# STM32MP21_CM33 register map
File version: 0.4
CPU: CM33 r0p1, little endian, MPU, FPU, vendor SysTick, 8 interrupt priority bits
Registers are 32-bit, read-write, reset 0x0 unless marked. A register's access mark holds for its fields unless they carry their own. Offsets are from the block's base; [hi:lo] are bit positions; lines under a group give offsets from that group; {n}, {i} and the like mark numbered series; 'fields as' and 'values as' point back to an identical list.

## DCMIPP (part 1 of 2) — DCMIPP register block
Base 0x48030000
Same registers: DCMIPP_S 0x58030000
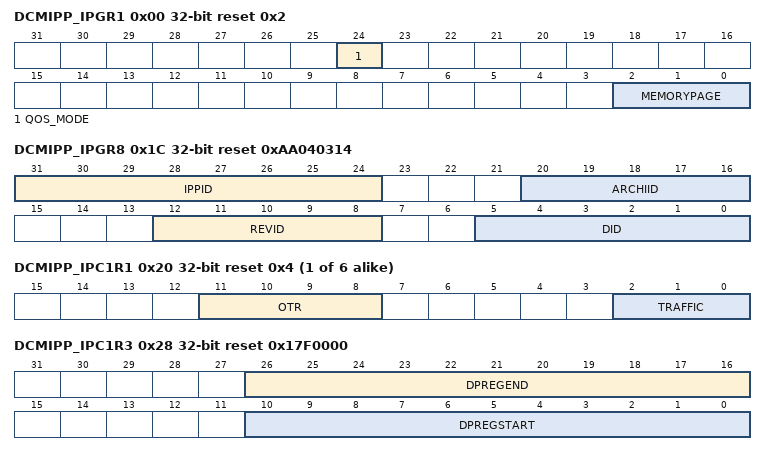
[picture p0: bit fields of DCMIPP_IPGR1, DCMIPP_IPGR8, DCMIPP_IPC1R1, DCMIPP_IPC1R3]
0x00 DCMIPP_IPGR1 reset 0x2 — DCMIPP IP-Plug global register 1
  [24] QOS_MODE — Quality of service
  [2:0] MEMORYPAGE — Memory page size, as power of 2 of 64-byte units:
    1=128 bytes; 2=256 bytes; 3=512 bytes; 4=1K bytes; 5=2K bytes; 6=4K bytes; 7=8K bytes
0x04 DCMIPP_IPGR2 — DCMIPP IP-Plug global register 2
  [0] PSTART — Request to lock the IP-Plug, to allow reconfiguration.
    0=No lock requested, IP-Plug runs on demand by background HW; 1=Lock requested: IP-Plug freezes shortly (see IDLE bit when lock is active)
0x08 DCMIPP_IPGR3 ro reset 0x1 — DCMIPP IP-Plug global register 3
  [0] IDLE — Status of IP-Plug
    0=IP-Plug is running (on demand by background HW); 1=IP-Plug is currently locked and can be reconfigured
0x1C DCMIPP_IPGR8 ro reset 0xAA040314 — DCMIPP IP-Plug identification register
  [31:24] IPPID — IP identifier (0xAA)
  [20:16] ARCHIID — Architecture identifier (0x04)
  [12:8] REVID — Revision identifier (0x03)
  [5:0] DID — Division identifier (0x14)
{0x10+0x10*i} DCMIPP_IPC{i}R1 reset 0x4 (i=1..6) — DCMIPP IP-Plug Clientx register 1
  [11:8] OTR — Maximum outstanding transactions
    0=Disabled; 1=Maximum two outstanding transactions ongoing
  [2:0] TRAFFIC — Burst size as power of 2 of 8-byte units
    0=8 bytes; 1=16 bytes; 2=32 bytes; 3=64 bytes; 4=128 bytes
{0x14+0x10*i} DCMIPP_IPC{i}R2 reset 0x10000 (i=1..6) — DCMIPP IP-Plug Clientx register 2
  [19:16] WLRU — Ratio for WLRU[3:0] arbitration
    0=Ratio part = 1; 1=Ratio part = 2; 15=Ratio part = 16
0x28 DCMIPP_IPC1R3 reset 0x17F0000 — DCMIPP IP-Plug Clientx register 3
  [26:16] DPREGEND — End word (AXI width = 64 bits) of the FIFO of Clientx.
  [10:0] DPREGSTART — Start word (AXI width = 64 bits) of the FIFO of Clientx.
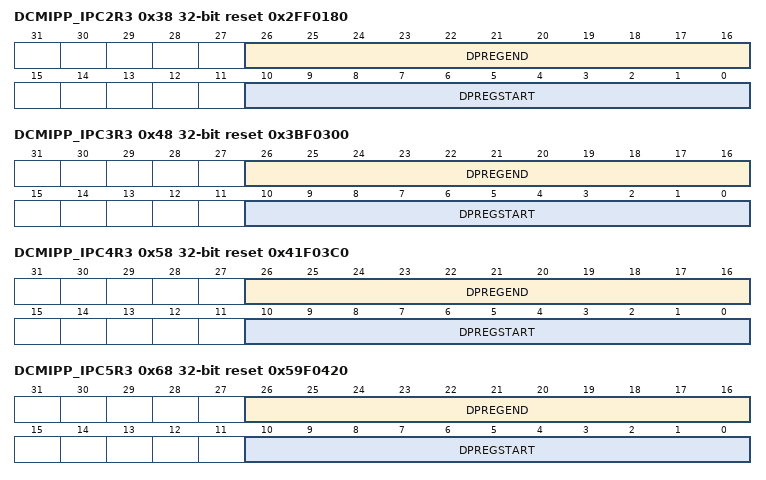
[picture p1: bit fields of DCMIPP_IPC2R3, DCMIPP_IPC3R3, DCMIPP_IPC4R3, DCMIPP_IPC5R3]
0x38 DCMIPP_IPC2R3 reset 0x2FF0180 — DCMIPP IP-Plug Clientx register 3
  fields as DCMIPP_IPC1R3
0x48 DCMIPP_IPC3R3 reset 0x3BF0300 — DCMIPP IP-Plug Clientx register 3
  fields as DCMIPP_IPC1R3
0x58 DCMIPP_IPC4R3 reset 0x41F03C0 — DCMIPP IP-Plug Clientx register 3
  fields as DCMIPP_IPC1R3
0x68 DCMIPP_IPC5R3 reset 0x59F0420 — DCMIPP IP-Plug Clientx register 3
  fields as DCMIPP_IPC1R3
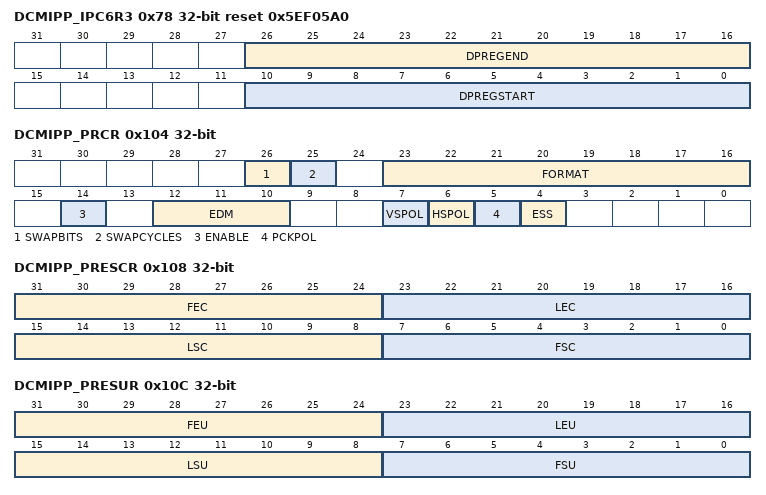
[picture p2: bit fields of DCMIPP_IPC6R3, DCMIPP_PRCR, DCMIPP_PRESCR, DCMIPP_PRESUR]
0x78 DCMIPP_IPC6R3 reset 0x5EF05A0 — DCMIPP IP-Plug Clientx register 3
  fields as DCMIPP_IPC1R3
0x104 DCMIPP_PRCR — DCMIPP parallel interface control register
  [26] SWAPBITS — Swap LSB vs.
    0=As received; 1=Swapped MSB vs
  [25] SWAPCYCLES — Swap data (cycle 0 vs.
    0=Default; 1=Swap active: the data of cycle 1 is used before the data of cycle 0
  [23:16] FORMAT — Other values: data are captured and output as-is only through the data/dump pipeline (forexample JPEG or byte input format).
    30=YUV422; 34=RGB565; 36=RGB888 (= YUV444); 42=RAW8; 43=RAW10; 44=RAW12; 45=RAW14; 74=monochrome 8-bit; 75=monochrome 10-bit; 76=monochrome 12-bit; 77=monochrome 14-bit; 90=byte stream (JPEG, compressed video)
  [14] ENABLE — Parallel interface enable
    0=Parallel interface disabled to lower power consumption; 1=Parallel interface enabled
  [12:10] EDM — Extended data mode
    0=Interface captures 8-bit data on every pixel clock; 1=Interface captures 10-bit data on every pixel clock; 2=Interface captures 12-bit data on every pixel clock; 3=Interface captures 14-bit data on every pixel clock; 4=Interface captures 16-bit data on every pixel clock
  [7] VSPOL — Vertical synchronization polarity
    0=VSYNC active low; 1=VSYNC active high
  [6] HSPOL — Horizontal synchronization polarity
    0=HSYNC active low; 1=HSYNC active high
  [5] PCKPOL — Pixel clock polarity
    0=Falling edge active; 1=Rising edge active
  [4] ESS — Embedded synchronization select
    0=Hardware synchronization data capture (frame/line start/stop) is synchronized with the HSYNC/VSYNC signals; 1=Embedded synchronization data capture is synchronized with synchronization codes embedded in the data flow
0x108 DCMIPP_PRESCR — DCMIPP parallel interface embedded synchronization code register
  [31:24] FEC — Frame end delimiter code
  [23:16] LEC — Line end delimiter code
  [15:8] LSC — Line start delimiter code
  [7:0] FSC — Frame start delimiter code
0x10C DCMIPP_PRESUR — DCMIPP parallel interface embedded synchronization unmask register
  [31:24] FEU — Frame end delimiter unmask
    0=The corresponding bit in the FEC byte in DCMIPP_ESCR is masked while comparing the frame end delimiter with the received data; 1=The corresponding bit in the FEC byte in DCMIPP_ESCR is compared while comparing the frame end delimiter with the received data
  [23:16] LEU — Line end delimiter unmask
    0=The corresponding bit in the LEC byte in DCMIPP_ESCR is masked while comparing the line end delimiter with the received data; 1=The corresponding bit in the LEC byte in DCMIPP_ESCR is compared while comparing the line end delimiter with the received data
  [15:8] LSU — Line start delimiter unmask
    0=The corresponding bit in the LSC byte in DCMIPP_ESCR is masked while comparing the line start delimiter with the received data; 1=The corresponding bit in the LSC byte in DCMIPP_ESCR is compared while comparing the line start delimiter with the received data
  [7:0] FSU — Frame start delimiter unmask
    0=The corresponding bit in the FSC byte in DCMIPP_ESCR is masked while comparing the frame start delimiter with the received data; 1=The corresponding bit in the FSC byte in DCMIPP_ESCR is compared while comparing the frame start delimiter with the received data
0x1F4 DCMIPP_PRIER — DCMIPP parallel interface interrupt enable register
  [6] ERRIE — Synchronization error interrupt enable
    0=No interrupt generation; 1=An interrupt is generated if the embedded synchronization codes are not received in the correct order
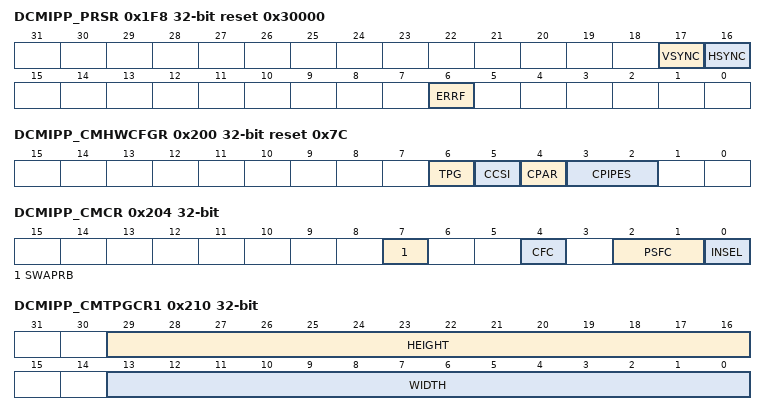
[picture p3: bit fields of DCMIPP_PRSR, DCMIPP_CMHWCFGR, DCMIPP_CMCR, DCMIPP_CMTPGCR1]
0x1F8 DCMIPP_PRSR ro reset 0x30000 — DCMIPP parallel interface status register
  [17] VSYNC — This bit gives the state of the VSYNC pin with the correct programmed polarity if ENABLE bit is set into the DCMIPP_PRCR register and if the pixel clock is received.
    0=Active frame; 1=Synchronization between frames
  [16] HSYNC — This bit gives the state of the HSYNC pin with the correct programmed polarity if ENABLE bit is set into the DCMIPP_PRCR register and if the pixel clock is received.
    0=Active line; 1=Synchronization between lines
  [6] ERRF — Synchronization error raw interrupt status
    0=No synchronization error detected; 1=Embedded synchronization characters are not received in the correct order
0x1FC DCMIPP_PRFCR wo — DCMIPP parallel interface interrupt clear register
  [6] CERRF — Synchronization error interrupt status clear
0x200 DCMIPP_CMHWCFGR ro reset 0x7C — DCMIPP common IP HW configuration register
  [6] TPG — Presence of the test pattern generator
    0=TPG is not implemented; 1=TPG is implemented
  [5] CCSI — Presence of the CSI-2 host interface
    0=No input from CSI-2 host; 1=Input from CSI-2 host is implemented (independently from the presence of CSI-2 host)
  [4] CPAR — Presence of the parallel interface
    0=Parallel interface input is not implemented; 1=Parallel interface input is implemented
  [3:2] CPIPES — Amount of instantiated pipes (either dump or pixel pipes)
0x204 DCMIPP_CMCR — DCMIPP common configuration register
  [7] SWAPRB — Swap R/U and B/V
    0=RGB/VYU; 1=BGR/UYV
  [4] CFC wo — Clear frame counter
  [2:1] PSFC — Pipe selection for the frame counter
    0=Frame counter mapped to Pipe0; 1=Frame counter mapped to Pipe1; 2=Frame counter mapped to Pipe2
  [0] INSEL — input selection
    0=DCMI; 1=CSI-2
0x208 DCMIPP_CMFRCR ro — DCMIPP common frame counter register
  [31:0] FRMCNT — Frame counter, read-only, loops around.
0x210 DCMIPP_CMTPGCR1 — DCMIPP common test pattern generator configuration register 1
  [29:16] HEIGHT — Height of the visible pixels of the generated frame
  [13:0] WIDTH — Width of the visible pixels of the generated frame
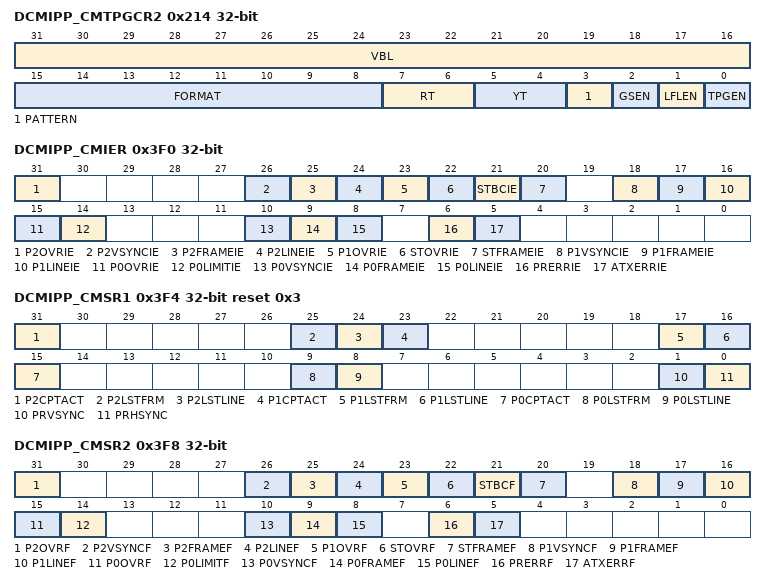
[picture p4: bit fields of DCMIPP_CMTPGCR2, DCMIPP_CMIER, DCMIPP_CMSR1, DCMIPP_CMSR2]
0x214 DCMIPP_CMTPGCR2 — DCMIPP common test pattern generator configuration register 2
  [31:16] VBL — Amount of lines of the vertical blanking
  [15:8] FORMAT — Pixel format generated:
    30=YUV422 (when selected, the YT field defines the YUV subformats); 34=RGB565; 36=RGB888; 42=RAW8 (when selected, or RAW10/12/14, RT[1:0] gives the component sequence); 43=RAW10; 44=RAW12; 45=RAW14; 74=monochrome 8-bit; 75=monochrome 10-bit; 76=monochrome 12-bit; 77=monochrome 14-bit
  [7:6] RT — Raw Bayer type
    0=RGGB; 1=GRBG; 2=GBRG; 3=BGGR
  [5:4] YT — YUV type
    {v}=BT (v=0..3)
  [3] PATTERN — Pattern selection, between color bars and color squares
    0=color bars, with the frame divided vertically into 8 bars of the respective colors: white,; 1=color squares, with the frame built of adjacent 256x256 color squares, each with a soft color gradient across each pixel
  [2] GSEN — Gray scale enable
    0=disabled, with differentiated RGB colors; 1=enabled, colors are converted into gray scales
  [1] LFLEN — Lifeline enable
    0=disabled, the lifeline is not visible; 1=enabled, the lifeline is both visible and progressing down of one line per frame
  [0] TPGEN — Test pattern generator enable
    0=disabled; 1=enabled, frames are generated continuously, indefinitely
0x3F0 DCMIPP_CMIER — DCMIPP common interrupt enable register
  [31] P2OVRIE — Overrun interrupt status enable for Pipe2
    0=No interrupt generation; 1=An interrupt is generated
  [26] P2VSYNCIE — Vertical sync interrupt enable for Pipe2
    0=No interrupt generation; 1=An interrupt is generated
  [25] P2FRAMEIE — Frame capture complete interrupt enable for Pipe2
    0=No interrupt generation; 1=An interrupt is generated
  [24] P2LINEIE — Multi-line capture complete interrupt enable for Pipe2
    0=No interrupt generation; 1=An interrupt is generated
  [23] P1OVRIE — Overrun interrupt enable for Pipe1
  [22] STOVRIE — Statistics overrun interrupt enable
    0=No interrupt generation; 1=An interrupt is generated if the AXI master is unable to transfer the last data before new data (32-bit) are received
  [21] STBCIE — Statistics bad configuration interrupt enable
    0=No interrupt generation; 1=An interrupt is generated if the software configuration is considered as non consistent
  [20] STFRAMEIE — Statistics frame capture completed interrupt enable
    0=No interrupt generation; 1=An interrupt is generated after the full capture of the statistics of a frame
  [18] P1VSYNCIE — Vertical sync interrupt enable for Pipe1
    0=No interrupt generation; 1=An interrupt is generated
  [17] P1FRAMEIE — Frame capture complete interrupt enable for Pipe1
    0=No interrupt generation; 1=An interrupt is generated
  [16] P1LINEIE — Multi-line capture complete interrupt status clear for Pipe1
    0=No interrupt generation; 1=An interrupt is generated
  [15] P0OVRIE — Overrun interrupt enable for Pipe0
    0=No interrupt generation; 1=An interrupt is generated
  [14] P0LIMITIE — Limit interrupt enable for Pipe0
    0=No interrupt generation; 1=An interrupt is generated
  [10] P0VSYNCIE — Vertical sync interrupt enable for Pipe0
    0=No interrupt generation; 1=An interrupt is generated
  [9] P0FRAMEIE — Frame capture complete interrupt enable for Pipe0
    0=No interrupt generation; 1=An interrupt is generated
  [8] P0LINEIE — Multi-line capture complete interrupt enable for Pipe0
    0=No interrupt generation; 1=An interrupt is generated
  [6] PRERRIE — Limit interrupt enable for the parallel Interface
    0=No interrupt generation; 1=An interrupt is generated
  [5] ATXERRIE — AXI transfer error interrupt enable for IP-Plug
    0=No interrupt generation; 1=An interrupt is generated
0x3F4 DCMIPP_CMSR1 ro reset 0x3 — DCMIPP common status register 1
  [31] P2CPTACT — Active frame capture (active from start-of-frame to frame complete) for Pipe2
    0=No capture currently active; 1=Capture currently active
  [25] P2LSTFRM — Last frame LSB bit, sampled at frame capture complete event for Pipe2
  [24] P2LSTLINE — Last line LSB bit, sampled at frame capture complete event for Pipe2
  [23] P1CPTACT — Active frame capture (active from start-of-frame to frame complete) for Pipe1
    0=No capture currently active; 1=Capture currently active
  [17] P1LSTFRM — Last frame LSB bit, sampled at frame capture complete event for Pipe1
  [16] P1LSTLINE — Last line LSB bit, sampled at Frame capture complete event for Pipe1
  [15] P0CPTACT — Active frame capture (active from start-of-frame to frame complete) for Pipe0
    0=No capture currently active; 1=Capture currently active
  [9] P0LSTFRM — Last frame LSB bit, sampled at Frame capture complete event for Pipe0
  [8] P0LSTLINE — Last line LSB bit, sampled at Frame capture complete event for Pipe0
  [1] PRVSYNC — This bit gives the state of the VSYNC pin with the correct programmed polarity on the parallel interface if ENABLE bit is set into the DCMIPP_PRCR register and if the pixel clock is received.
    0=Active frame; 1=Synchronization between frames
  [0] PRHSYNC — This bit gives the state of the HSYNC pin with the correct programmed polarity on the parallel interface if ENABLE bit is set into the DCMIPP_PRCR register and if the pixel clock is received.
    0=Active line; 1=Synchronization between lines
0x3F8 DCMIPP_CMSR2 ro — DCMIPP common status register 2
  [31] P2OVRF — Overrun raw interrupt status for Pipe2
    0=No data buffer overrun occurred; 1=A data buffer overrun occurred, and this frame data are corrupted
  [26] P2VSYNCF — VSYNC raw interrupt status for Pipe2
  [25] P2FRAMEF — Frame capture completed raw interrupt status for Pipe2
    0=No capture or ongoing capture; 1=All data of a frame have been captured
  [24] P2LINEF — Multi-line capture completed raw interrupt status for Pipe2
  [23] P1OVRF — Overrun raw interrupt status for Pipe1
    0=No data buffer overrun occurred; 1=A data buffer overrun occurred and this frame data are corrupted
  [22] STOVRF — Statistics overrun interrupt status
    0=No overrun occurred; 1=An overrun occurred
  [21] STBCF — Statistics bad configuration interrupt status
    0=No overrun occurred; 1=An overrun occurred
  [20] STFRAMEF — Statistics frame capture completed interrupt enable
    0=No overrun occurred; 1=An overrun occurred
  [18] P1VSYNCF — VSYNC raw interrupt status for Pipe1
  [17] P1FRAMEF — Frame capture completed raw interrupt status for Pipe1
    values as P2FRAMEF
  [16] P1LINEF — Multi-line capture completed raw interrupt status for Pipe1
  [15] P0OVRF — Overrun raw interrupt status for Pipe0
    values as P1OVRF
  [14] P0LIMITF — Limit raw interrupt status for Pipe0
  [10] P0VSYNCF — VSYNC raw interrupt status for Pipe0
  [9] P0FRAMEF — Frame capture completed raw interrupt status for Pipe0
    values as P2FRAMEF
  [8] P0LINEF — Multi-line capture completed raw interrupt status for Pipe0
  [6] PRERRF — Synchronization error raw interrupt status for the parallel interface.
    values as DCMIPP_PRSR.ERRF
  [5] ATXERRF — AXI transfer error interrupt status flag for the IP-Plug.
    0=No AXI transfer error detected; 1=AXI transfer error occurred on an AXI client
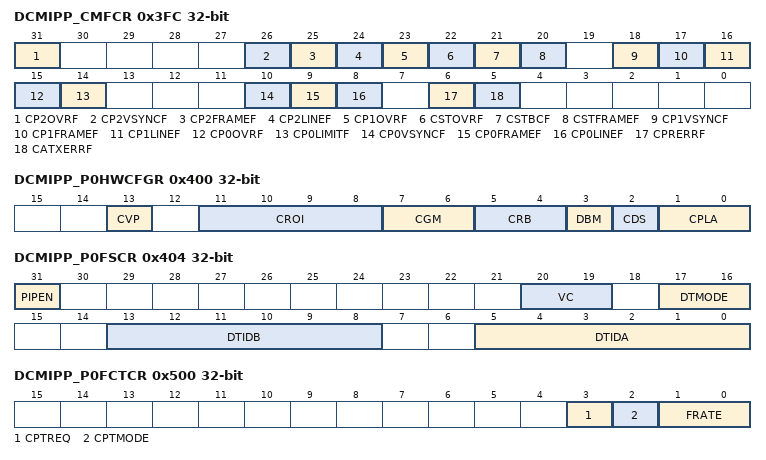
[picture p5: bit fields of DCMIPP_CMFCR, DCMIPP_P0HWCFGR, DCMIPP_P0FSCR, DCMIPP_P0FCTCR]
0x3FC DCMIPP_CMFCR wo — DCMIPP common interrupt clear register
  [31] CP2OVRF — Overrun interrupt status clear
  [26] CP2VSYNCF — Vertical synchronization interrupt status clear
  [25] CP2FRAMEF — Frame capture complete interrupt status clear
  [24] CP2LINEF — Multi-line capture complete interrupt status clear
  [23] CP1OVRF — Overrun interrupt status clear
  [22] CSTOVRF — Statistics overrun interrupt clear
  [21] CSTBCF — Statistics bad configuration interrupt enable
  [20] CSTFRAMEF — Statistics frame capture completed interrupt enable
  [18] CP1VSYNCF — Vertical synchronization interrupt status clear
  [17] CP1FRAMEF — Frame capture complete interrupt status clear
  [16] CP1LINEF — Multi-line capture complete interrupt status clear
  [15] CP0OVRF — Overrun interrupt status clear
  [14] CP0LIMITF — limit interrupt status clear
  [10] CP0VSYNCF — Vertical synchronization interrupt status clear
  [9] CP0FRAMEF — Frame capture complete interrupt status clear
  [8] CP0LINEF — Multi-line capture complete interrupt status clear
  [6] CPRERRF — Synchronization error interrupt status clear
  [5] CATXERRF — AXI transfer error interrupt status clear
0x400 DCMIPP_P0HWCFGR ro — DCMIPP Pipe0 HW configuration register
  [13] CVP — Capability for pipeline virtualization
    0=No virtualization for the pipe; 1=Virtualization mechanism implemented for the pipe
  [11:8] CROI — Capability for ROI: defines the number of ROIs in the pipe
  [7:6] CGM — Capability for gamma conversions
    0=No gamma conversion; 1=Gamma conversion with three interpolated segments
  [5:4] CRB — Capability for demosaicing
    0=No demosaicing; 1=Demosaicing with 2018-03 algorithm (Matrix 3 x 3 with Edge/LineHV/Peak)
  [3] DBM — Double buffer mode
    0=No Double buffer mode supported; 1=Double buffer mode supported
  [2] CDS — Capability for downsize filter
    0=No downsize filter, basic decimation instead; 1=Downsize filter based on a BoxFilter
  [1:0] CPLA — Capability for planar buffers
    0=Capability to dump to a coplanar buffer only; 1=Capability to dump to a semi-planar buffer (i; 2=Capability to dump to full-planar buffer (i
0x404 DCMIPP_P0FSCR — DCMIPP Pipe0 flow selection configuration register
  [31] PIPEN — Activation of PipeN
    0=Pipe disabled; 1=Pipe enabled, can start capturing with CPTMODE, CPTREQ, CPTACK
  [20:19] VC — Flow selection mode
  [17:16] DTMODE — Flow selection mode
    0=Only flow DTIDA from the selected virtual channel is forwarded in the pipe; 1=Flows DTIDA and/or DTIDB from the selected virtual channel are forwarded in the pipe; 2=All data types from the selected virtual channel (except the DTIDA or DTIDB) are forwarded in the pipe; 3=All data types of the selected virtual channel VC are forwarded in the pipe
  [13:8] DTIDB — Data type selection ID B
  [5:0] DTIDA — Data type selection ID A
0x500 DCMIPP_P0FCTCR — DCMIPP Pipe0 flow control configuration register
  [3] CPTREQ — Capture requested
    0=Capture not requested for next frame; 1=Capture requested for next frame
  [2] CPTMODE — Capture mode
    0=Continuous grab mode - The received data are transferred into the destination memory through the AXI master; 1=Snapshot mode (single frame) - Once activated, the interface waits for the start of frame, and then transfers a single frame through the AXI master
  [1:0] FRATE — Frame capture rate control
    0=All frames are captured; 1=one out of two frames captured (50% bandwidth reduction); 2=one out of four frames captured (75% bandwidth reduction); 3=one out of eight frames captured (87% bandwidth reduction)
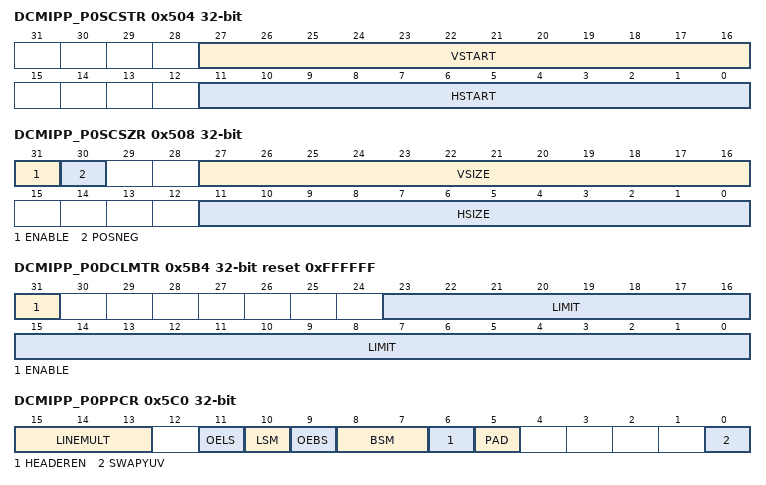
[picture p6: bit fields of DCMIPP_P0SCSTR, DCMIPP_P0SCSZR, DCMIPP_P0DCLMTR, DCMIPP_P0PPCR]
0x504 DCMIPP_P0SCSTR — DCMIPP Pipe0 statistic/crop start register
  [27:16] VSTART — Vertical start, from 0 to 4094 pixels high
  [11:0] HSTART — Horizontal start, from 0 to 4094 words wide
0x508 DCMIPP_P0SCSZR — DCMIPP Pipe0 statistic/crop size register
  [31] ENABLE — This bit is set and cleared by software.
    0=Bypass; 1=Enable
  [30] POSNEG — This bit is set and cleared by software.
    0=Positive area, the rectangle defined by VSIZE, HSIZE, and VSTART, HSTART; 1=Negative area, the area excluding the rectangle defined by VSIZE, HSIZE, and VSTART, HSTART
  [27:16] VSIZE — Vertical size, from 0 to 4094 pixels high
  [11:0] HSIZE — Horizontal size, from 0 to 4094 word wide (data 32-bit)
0x5B0 DCMIPP_P0DCCNTR ro — DCMIPP Pipe0 dump counter register
  [25:0] CNT — Number of data dumped during the frame.
0x5B4 DCMIPP_P0DCLMTR reset 0xFFFFFF — DCMIPP Pipe0 dump limit register
  [31] ENABLE
    0=Disabled, no check on the amount of 32-bit words transmitted; 1=Enabled, check done versus limit
  [23:0] LIMIT — Maximum number of 32-bit data that can be dumped during a frame, after the crop 2D operation.
0x5C0 DCMIPP_P0PPCR — DCMIPP Pipe0 pixel packer configuration register
  [15:13] LINEMULT — Amount of capture completed lines for LINE event and interrupt
    0=Event after one line; 1=Event after two lines; 2=Event after four lines; 3=Event after eight lines; 4=Event after sixteen lines; 5=Event after 32 lines; 6=Event after 64 lines; 7=Event after 128 lines
  [11] OELS — Odd/even line select (line select start)
    0=Interface captures first line after the frame start, second one is dropped; 1=Interface captures second line from the frame start, first one is dropped
  [10] LSM — Line select mode
    0=Interface captures all received lines; 1=Interface captures one line out of two
  [9] OEBS — Odd/even byte select (byte select start)
    0=Interface captures the first data (byte or double byte) from the frame/line start, the second one is dropped; 1=Interface captures the second data (byte or double byte) from the frame/line start, the first one is dropped
  [8:7] BSM — Byte select mode
    0=Interface captures all received data; 1=Interface captures 1 data out of 2; 2=Interface captures one byte out of four; 3=Interface captures two bytes out of four
  [6] HEADEREN — CSI header dump enable
    0=CSI-2 headers are not dumped; 1=CSI-2 headers are dumped as a 32-bit word
  [5] PAD — Pad mode for monochrome and raw Bayer 10/12/14 bpp (MSB vs.
    0=Aligns on LSB (and pads null bits on MSB), for backward compatibility with former DCMI; 1=Aligns on MSB (and pads null bits on LSB), for better ease of software or GPU
  [0] SWAPYUV — Swaps, within a 32-bit word, byte 0-vs-1 and byte 2-vs-3.
    0=Outputs the provided words, as described in Section43; 1=Swaps the bytes from provided words, byte 0-vs
{0x5C4+0x400*i} DCMIPP_P{i}PPM0AR1 (i=0..2) — DCMIPP Pipe{i} pixel packer Memory0 address register 1
  [31:0] M0A — Memory0 address
0x5D0 DCMIPP_P0STM0AR ro — DCMIPP Pipe0 status Memory0 address register
  [31:0] M0A — Memory0 address
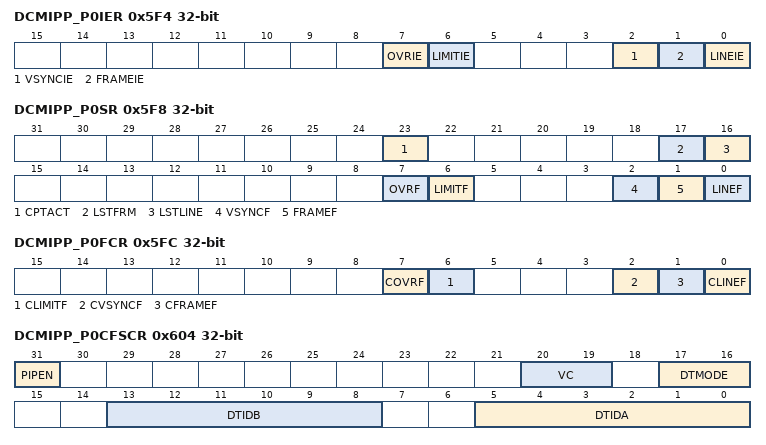
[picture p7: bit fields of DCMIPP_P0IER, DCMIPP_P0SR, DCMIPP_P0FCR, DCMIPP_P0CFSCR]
0x5F4 DCMIPP_P0IER — DCMIPP Pipe0 interrupt enable register
  [7] OVRIE — Overrun interrupt enable
    values as DCMIPP_CMIER.STOVRIE
  [6] LIMITIE — Limit interrupt enable
    0=No interrupt generation when the limit is reached; 1=An interrupt is generated when the limit is reached
  [2] VSYNCIE — VSYNC interrupt enable
    0=No interrupt generation; 1=An interrupt is generated on each VSYNC (captured or not)
  [1] FRAMEIE — Frame capture completed interrupt enable
    0=No interrupt generation; 1=An interrupt is generated after the full capture of a cropped frame
  [0] LINEIE — Multi-line capture completed interrupt enable
    0=No interrupt generation when the line is received; 1=An interrupt is generated after the full capture of a group of lines (or last line reached)
0x5F8 DCMIPP_P0SR ro — DCMIPP Pipe0 status register
  [23] CPTACT — Capture immediate status
    0=Capture currently inactive; 1=Capture currently active
  [17] LSTFRM — Last frame LSB bit, sampled at frame capture complete event.
  [16] LSTLINE — Last line LSB bit, sampled at frame capture complete event.
  [7] OVRF — Overrun raw interrupt status
    values as DCMIPP_CMSR2.P1OVRF
  [6] LIMITF — Limit raw interrupt status
  [2] VSYNCF — VSYNC raw interrupt status
  [1] FRAMEF — Frame capture completed raw interrupt status
    values as DCMIPP_CMSR2.P2FRAMEF
  [0] LINEF — Multi-line capture completed raw interrupt status
0x5FC DCMIPP_P0FCR wo — DCMIPP Pipe0 interrupt clear register
  [7] COVRF — Overrun interrupt status clear
  [6] CLIMITF — limit interrupt status clear
  [2] CVSYNCF — Vertical synchronization interrupt status clear
  [1] CFRAMEF — Frame capture complete interrupt status clear
  [0] CLINEF — Multi-line capture complete interrupt status clear
0x604 DCMIPP_P0CFSCR ro — DCMIPP Pipe0 current flow selection configuration register
  [31] PIPEN — Current activation of PipeN
    values as DCMIPP_P0FSCR.PIPEN
  [20:19] VC — Current flow selection mode
  [17:16] DTMODE — Flow selection mode
    0=Only flow DTIDA from the selected virtual channel is forwarded in the pipe; 1=Flows DTIDA and/or DTIDB from the selected virtual channel are forwarded in the pipe; 2=All Datatypes from the selected virtual channel, except the DTIDA or DTIDB are forwarded into the pipe; 3=All Datatypes of the selected virtual channel VC are forwarded in the pipe
  [13:8] DTIDB — Current data type selection ID B
  [5:0] DTIDA — Current data type selection ID A
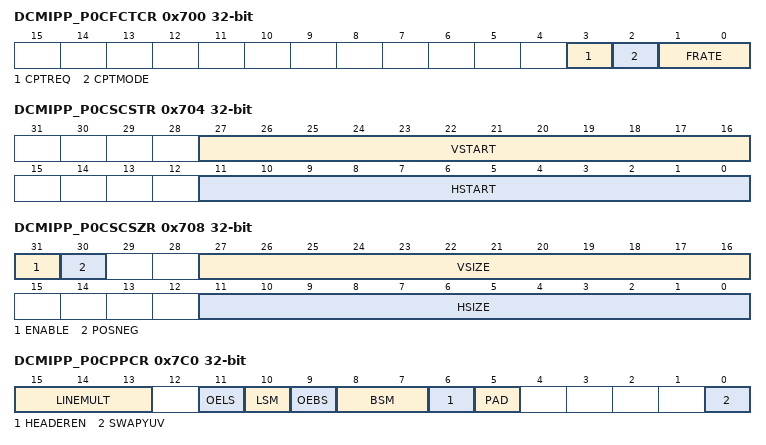
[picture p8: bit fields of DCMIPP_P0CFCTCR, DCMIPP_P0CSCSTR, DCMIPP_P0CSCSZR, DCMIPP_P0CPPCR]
0x700 DCMIPP_P0CFCTCR ro — DCMIPP Pipe0 current flow control configuration register
  [3] CPTREQ — Capture requested
    values as DCMIPP_P0FCTCR.CPTREQ
  [2] CPTMODE — Capture mode
    values as DCMIPP_P0FCTCR.CPTMODE
  [1:0] FRATE — Frame capture rate control
    0=all frames are captured; 1=one out of two frames captured (50% bandwidth reduction); 2=one out of four frames captured (75% bandwidth reduction); 3=one out of eight frames captured (87% bandwidth reduction)
0x704 DCMIPP_P0CSCSTR ro — DCMIPP Pipe0 current statistic/crop start register
  [27:16] VSTART — Current vertical start, from 0 to 4094 pixels high
  [11:0] HSTART — Current horizontal start, from 0 to 4094 words wide
0x708 DCMIPP_P0CSCSZR ro — DCMIPP Pipe0 current statistic/crop size register
  [31] ENABLE — Current value of the ENABLE bit
    0=Bypass; 1=Enable: Depending on bit POSNEG value, the rectangle defined by the VSIZE, HSIZE, VSTART, HSTART can be used to extract or to remove certain amount of data (statistical extraction or removal, or basic 2D crop features)
  [30] POSNEG — Current value of the POSNEG bit
    0=Positive area; 1=Negative area
  [27:16] VSIZE — Current vertical size, from 0 to 4094 pixels high.
  [11:0] HSIZE — Current horizontal size, from 0 to 4094 word wide (data 32-bit).
0x7C0 DCMIPP_P0CPPCR ro — DCMIPP Pipe0 current pixel packer configuration register
  [15:13] LINEMULT — Current amount of capture completed lines for LINE event and interrupt
    0=Event after every line; 1=Event after two lines; 2=Event after four lines; 3=Event after eight lines; 4=Event after sixteen lines; 5=Event after 32 lines; 6=Event after 64 lines; 7=Event after 128 lines
  [11] OELS — Current odd/even line select (ine select start)
    0=Interface captures the first line after the frame start, the second one is dropped; 1=Interface captures the second line from the frame start, the first one is dropped
  [10] LSM — Current Line select mode
    values as DCMIPP_P0PPCR.LSM
  [9] OEBS — Current odd/even byte select (byte select start)
    values as DCMIPP_P0PPCR.OEBS
  [8:7] BSM — Current Byte select mode
    0=Interface captures all received data; 1=Interface captures one data out of two; 2=Interface captures one byte out of four; 3=Interface captures two bytes out of four
  [6] HEADEREN — Current CSI header dump enable
    0=CSI-2 headers are not dumped; 1=CSI-2 headers are dumped as 32-bit words
  [5] PAD — Current Pad mode for monochrome and raw Bayer 10/12/14 bpp (MSB vs.
    values as DCMIPP_P0PPCR.PAD
  [0] SWAPYUV — Swaps, within a 32-bit word, byte 0 vs.
    0=Outputs the provided words, as described in Section43; 1=Swaps the bytes from provided words, byte 0 vs
{0x7C4+0x400*i} DCMIPP_P{i}CPPM0AR1 ro (i=0..2) — DCMIPP Pipe{i} current pixel packer Memory0 address register 1
  [31:0] M0A — Memory0 address
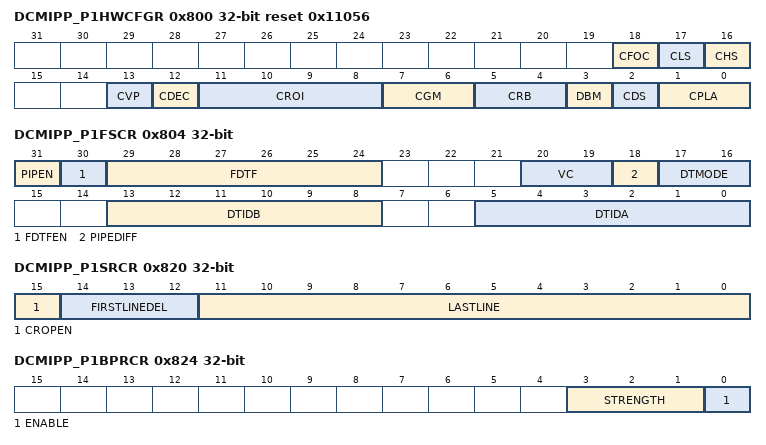
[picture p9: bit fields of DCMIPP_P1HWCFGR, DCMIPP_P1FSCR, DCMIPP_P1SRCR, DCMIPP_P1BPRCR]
0x800 DCMIPP_P1HWCFGR ro reset 0x11056 — DCMIPP Pipex HW configuration register
  [18] CFOC — Capability for focus extraction
    0=Focus extraction not supported; 1=Focus extraction supported
  [17] CLS — Capability for lens shading
    0=Lens shading not supported; 1=Lens shading supported
  [16] CHS — Capability to extract histograms
    0=Histogram extraction not supported; 1=Histogram extraction supported
  [13] CVP — Capability for pipeline virtualization
    values as DCMIPP_P0HWCFGR.CVP
  [12] CDEC — Capability to decimate before downsize
    0=No decimation supported; 1=Decimation before downsize supported
  [11:8] CROI — Capability for ROI: defines the number of ROIs in the pipe
  [7:6] CGM — Capability for gamma conversions
    0=No gamma conversion; 1=Gamma conversion with seven interpolated segments
  [5:4] CRB — Capability for demosaicing
    values as DCMIPP_P0HWCFGR.CRB
  [3] DBM — Double buffer mode
    values as DCMIPP_P0HWCFGR.DBM
  [2] CDS — Capability for downsize filter
    values as DCMIPP_P0HWCFGR.CDS
  [1:0] CPLA — Capability for planar buffers
    values as DCMIPP_P0HWCFGR.CPLA
0x804 DCMIPP_P1FSCR — DCMIPP Pipe1 flow selection configuration register
  [31] PIPEN — Activation of PipeN
    values as DCMIPP_P0FSCR.PIPEN
  [30] FDTFEN — Force Datatype format enable
    0=Disable force Datatype format
  [29:24] FDTF — Force Datatype format
  [20:19] VC — Flow selection mode
  [18] PIPEDIFF — Differentiates Pipe2 from Pipe1
    0=Pipe2 receives the same data as Pipe1 (data filtered by Pipe1 configuration for VC and DTIDA/DTIDB and DTMODE mode, as well as FDTF and FDTFEN bit); 1=Pipe1 gets pixels only from VC and DT configured in Pipe1, processed by all blocks belonging to the image processing functional block (demosaicing, auto exposure, statistics, contrast enhancement)
  [17:16] DTMODE — Flow selection mode
    0=Only flow DTIDA from the selected virtual channel is forwarded in the pipe; 1=Flows DTIDA and/or DTIDB from the selected virtual channel are forwarded in the pipe
  [13:8] DTIDB — Data type selection ID B
  [5:0] DTIDA — Data type selection ID A
0x820 DCMIPP_P1SRCR — DCMIPP Pipe1 stat removal configuration register
  [15] CROPEN — Crop line enable
    0=No crop (all pixels are fed through); 1=Crop
  [14:12] FIRSTLINEDEL — Amount of first lines to delete when CROPEN = 1
  [11:0] LASTLINE — Amount of following lines to keep when CROPEN = 1.
0x824 DCMIPP_P1BPRCR — DCMIPP Pipe1 bad pixel removal control register
  [3:1] STRENGTH — Strength (aggressiveness) of the bad pixel detection
    0=The filter is fairly tolerant: only a few pixels are declared bad, due to their high noise; 7=The filter is very aggressive: many pixels are declared bad, even if only slightly noisy
  [0] ENABLE — Bad pixel detection must be enabled only for raw Bayer flows, as it corrupts RGB flows.
    0=Bypass: bad pixel removal is not active, all pixels are transmitted through; 1=Enable: if bad pixel are detected, they are replaced by corrected pixels
0x828 DCMIPP_P1BPRSR ro — DCMIPP Pipe1 bad pixel removal status register
  [11:0] BADCNT — Amount of detected bad pixels
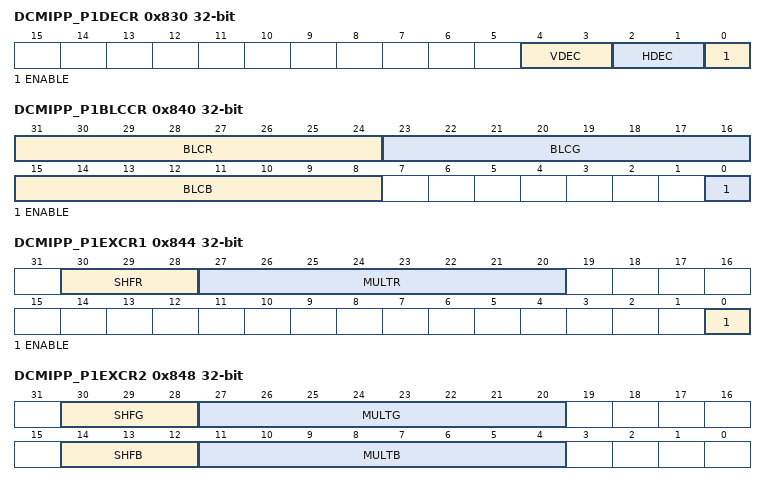
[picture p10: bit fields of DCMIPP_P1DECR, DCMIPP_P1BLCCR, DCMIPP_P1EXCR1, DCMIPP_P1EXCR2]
0x830 DCMIPP_P1DECR — DCMIPP Pipe1 decimation register
  [4:3] VDEC — Vertical decimation ratio
    0=All pixels are transmitted, no vertical decimation; 1=one line out of two transmitted (for raw Bayer data, two lines of components every four); 2=one line out of four transmitted (for raw Bayer data, two lines of components every eight); 3=one line out of eight transmitted (for raw Bayer data, two lines of components every 16)
  [2:1] HDEC — Horizontal decimation ratio
    0=All pixels are transmitted, no horizontal decimation; 1=one line out of two transmitted (for raw Bayer data, two lines of components every four); 2=one line out of four transmitted (for raw Bayer data, two lines of components every eight); 3=one line out of eight transmitted (for raw Bayer data, two lines of components every 16)
  [0] ENABLE
    0=Bypass: decimation is not active, all pixels are transmitted; 1=Enable: one pixel every 1, 2, 4, or 8, in H and V is transmitted, following HDEC and VDEC
0x840 DCMIPP_P1BLCCR — DCMIPP Pipe1 black level calibration control register
  [31:24] BLCR — Black level calibration - Red
  [23:16] BLCG — Black level calibration - Green
  [15:8] BLCB — Black level calibration - Blue
  [0] ENABLE — Black level calibration
    0=Bypass: black level calibration is not active, all pixels are transmitted non-modified; 1=Enable: the BLC R, G, B are subtracted
0x844 DCMIPP_P1EXCR1 — DCMIPP Pipe1 exposure control register 1
  [30:28] SHFR — Exposure shift - Red
  [27:20] MULTR — Exposure multiplier - Red
  [0] ENABLE — Exposure control (multiplication and shift) of all red, green and blue
    0=Bypass: exposure multiplier and shift are not applied; 1=Enable: the exposure multiplication and shift is applied
0x848 DCMIPP_P1EXCR2 — DCMIPP Pipe1 exposure control register 2
  [30:28] SHFG — Exposure shift - Green
  [27:20] MULTG — Exposure multiplier - Green
  [14:12] SHFB — Exposure shift - Blue
  [11:4] MULTB — Exposure multiplier - Blue
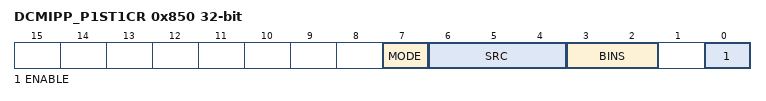
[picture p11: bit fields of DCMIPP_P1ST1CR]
0x850 DCMIPP_P1ST1CR — DCMIPP Pipe1 statistics1 control register
  [7] MODE — Statistics mode
    0=Average: accumulates the 8-bit component value of the considered pixel components; 1=Bins: accumulates 256 for each considered pixel component fitting a bin dynamic
  [6:4] SRC — Statistics source
  [3:2] BINS — Current bin definition
    0=B_0x0_MODE__EQUAL_BINS (LowerBins: Accu0 (1, 2) is incremented of 256 if Component less than4 (less than8, less than16)); 1=B_0x1_MODE__EQUAL_BINS (LowMid Bins: Accu0 (1, 2) is incremented of 256 if Component less than32 (less than64, less than128)); 2=B_0x2_MODE__EQUAL_BINS (UpMid Bins: Accu0 (1, 2) is incremented of 256 if Component >127 (>191, >224)); 3=B_0x3_MODE__EQUAL_BINS (UpBins: Accu0 (1, 2) is incremented of 256 if Component >239 (>247, >251))
  [0] ENABLE
    0=Disabled: statistics are not accumulated; 1=Enable: statistics are accumulated
